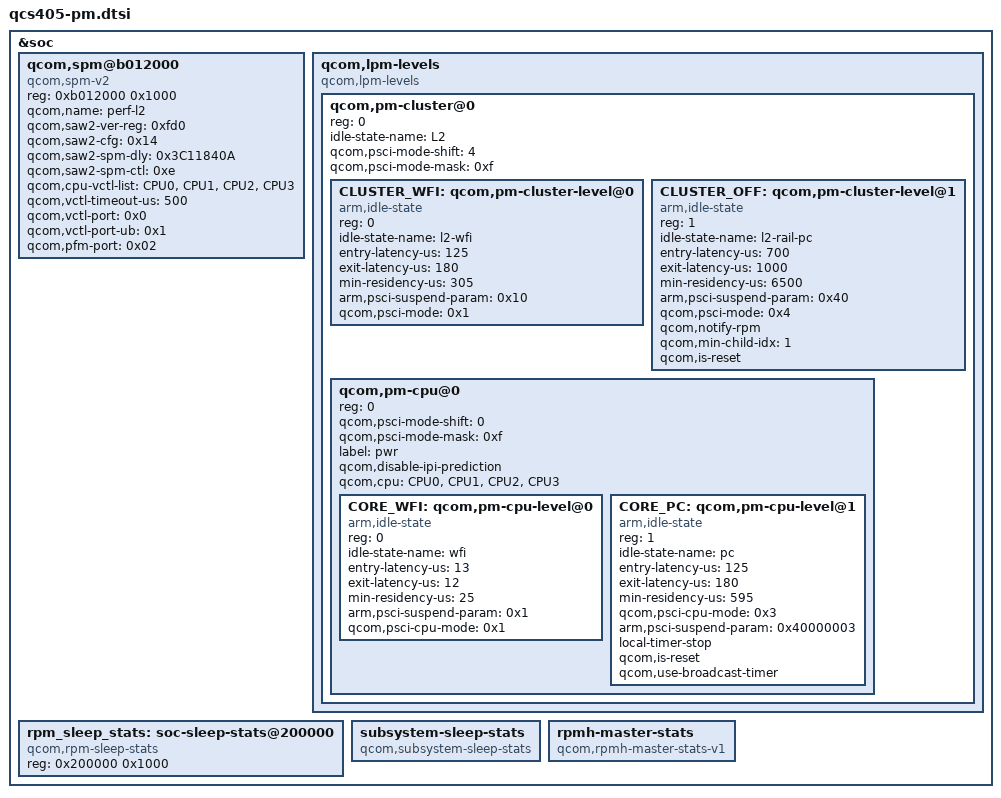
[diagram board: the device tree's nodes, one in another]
&soc {
	qcom,spm@b012000 {
		compatible = "qcom,spm-v2";
		#address-cells = <1>;
		#size-cells = <1>;
		reg = <0xb012000 0x1000>;
		qcom,name = "perf-l2";
		qcom,saw2-ver-reg = <0xfd0>;
		qcom,saw2-cfg = <0x14>;
		qcom,saw2-spm-dly= <0x3C11840A>;
		qcom,saw2-spm-ctl = <0xe>;
		qcom,cpu-vctl-list = <&CPU0 &CPU1 &CPU2 &CPU3>;
		qcom,vctl-timeout-us = <500>;
		qcom,vctl-port = <0x0>;
		qcom,vctl-port-ub = <0x1>;
		qcom,pfm-port = <0x02>;
	};

	qcom,lpm-levels {
		compatible = "qcom,lpm-levels";
		#address-cells = <1>;
		#size-cells = <0>;

		qcom,pm-cluster@0 {
			reg = <0>;
			#address-cells = <1>;
			#size-cells = <0>;
			idle-state-name = "L2";
			qcom,psci-mode-shift = <4>;
			qcom,psci-mode-mask = <0xf>;

			CLUSTER_WFI: qcom,pm-cluster-level@0 { /* D1 */
				reg = <0>;
				compatible = "arm,idle-state";
				idle-state-name = "l2-wfi";
				entry-latency-us = <125>;
				exit-latency-us = <180>;
				min-residency-us = <305>;
				arm,psci-suspend-param = <0x10>;
				qcom,psci-mode = <0x1>;
			};

			CLUSTER_OFF: qcom,pm-cluster-level@1 { /* D4 */
				reg = <1>;
				compatible = "arm,idle-state";
				idle-state-name = "l2-rail-pc";
				entry-latency-us = <700>;
				exit-latency-us = <1000>;
				min-residency-us = <6500>;
				arm,psci-suspend-param = <0x40>;
				qcom,psci-mode = <0x4>;
				qcom,notify-rpm;
				qcom,min-child-idx = <1>;
				qcom,is-reset;
			};

			qcom,pm-cpu@0 {
				reg = <0>;
				#address-cells = <1>;
				#size-cells = <0>;
				qcom,psci-mode-shift = <0>;
				qcom,psci-mode-mask = <0xf>;
				label = "pwr";
				qcom,disable-ipi-prediction;
				qcom,cpu = <&CPU0 &CPU1 &CPU2 &CPU3>;

				CORE_WFI: qcom,pm-cpu-level@0 { /* C1 */
					reg = <0>;
					compatible = "arm,idle-state";
					idle-state-name = "wfi";
					entry-latency-us = <13>;
					exit-latency-us = <12>;
					min-residency-us = <25>;
					arm,psci-suspend-param = <0x1>;
					qcom,psci-cpu-mode = <0x1>;
				};

				CORE_PC: qcom,pm-cpu-level@1 {  /* C3 */
					reg = <1>;
					compatible = "arm,idle-state";
					idle-state-name = "pc";
					entry-latency-us = <125>;
					exit-latency-us = <180>;
					min-residency-us = <595>;
					qcom,psci-cpu-mode = <0x3>;
					arm,psci-suspend-param = <0x40000003>;
					local-timer-stop;
					qcom,is-reset;
					qcom,use-broadcast-timer;
				};
			};
		};
	};

	rpm_sleep_stats: soc-sleep-stats@200000 {
		compatible = "qcom,rpm-sleep-stats";
		reg = <0x200000  0x1000>;
	};

	subsystem-sleep-stats {
		compatible = "qcom,subsystem-sleep-stats";
	};

	rpmh-master-stats {
		compatible = "qcom,rpmh-master-stats-v1";
	};
};
